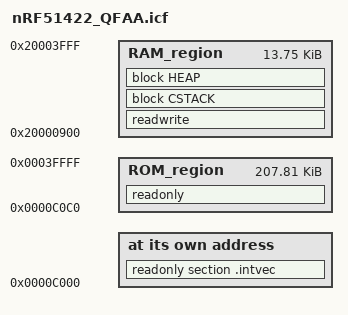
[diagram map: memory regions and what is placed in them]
/*###ICF### Section handled by ICF editor, don't touch! ****/
/*-Editor annotation file-*/
/* IcfEditorFile="$TOOLKIT_DIR$\config\ide\IcfEditor\cortex_v1_0.xml" */
/*-Specials-*/
/*-Memory Regions-*/

/* Softdevice 2.0 (51422 rev. CA and C0) */
//define symbol __ICFEDIT_intvec_start__ = 0x0000A000;
//define symbol __ICFEDIT_region_ROM_start__ = 0x0000A100;

/* Softdevice 3.0 (51422 rev. DA and E0) */
define symbol __ICFEDIT_intvec_start__ = 0x0000C000;
define symbol __ICFEDIT_region_ROM_start__ = 0x0000C0C0;

/* Softdevice 4.0 (51422 rev. Fx0, Ax0, Bx0) */
//define symbol __ICFEDIT_intvec_start__ = 0x0000D000;
//define symbol __ICFEDIT_region_ROM_start__ = 0x0000D100;

define symbol __ICFEDIT_region_ROM_end__   = 0x0003FFFF;
define symbol __ICFEDIT_region_RAM_start__ = 0x20000900;
define symbol __ICFEDIT_region_RAM_end__   = 0x20003FFF;

/*-Sizes-*/
define symbol __ICFEDIT_size_cstack__ = 2048;
define symbol __ICFEDIT_size_heap__   = 2048;
/**** End of ICF editor section. ###ICF###*/

define memory mem with size = 4G;
define region ROM_region   = mem:[from __ICFEDIT_region_ROM_start__   to __ICFEDIT_region_ROM_end__];
define region RAM_region   = mem:[from __ICFEDIT_region_RAM_start__   to __ICFEDIT_region_RAM_end__];

define block CSTACK    with alignment = 8, size = __ICFEDIT_size_cstack__   { };
define block HEAP      with alignment = 8, size = __ICFEDIT_size_heap__     { };

initialize by copy { readwrite };
do not initialize  { section .noinit };

keep { section .intvec };
place at address mem:__ICFEDIT_intvec_start__ { readonly section .intvec };
place in ROM_region   { readonly };
place in RAM_region   { readwrite,
                        block CSTACK,
                        block HEAP };
